# STM32WL3Rx register map
File version: 1.0
Registers are 32-bit, read-write, reset 0x0 unless marked. A register's access mark holds for its fields unless they carry their own. Offsets are from the block's base; [hi:lo] are bit positions; {n}, {i} and the like mark numbered series.

## FLASH — FLASH (FLASH)
Base 0x40001000
0x00 COMMAND — (@ 0x00000000) Command register
  [7:0] COMMAND
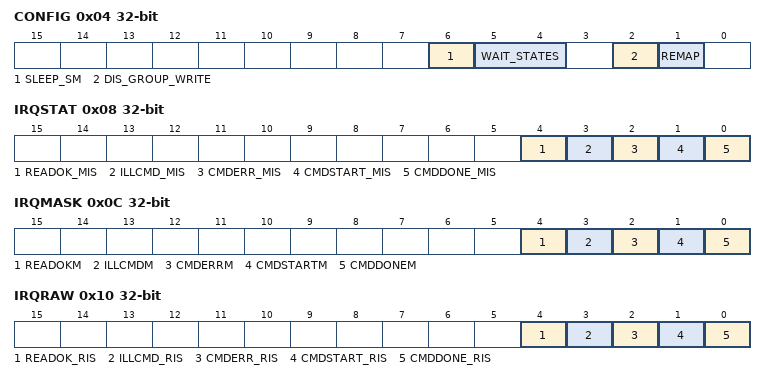
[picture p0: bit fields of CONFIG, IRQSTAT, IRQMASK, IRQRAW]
0x04 CONFIG — (@ 0x00000004) Configuration register
  [6] SLEEP_SM, [5:4] WAIT_STATES, [2] DIS_GROUP_WRITE, [1] REMAP
0x08 IRQSTAT — (@ 0x00000008) Interrupt status register
  [4] READOK_MIS, [3] ILLCMD_MIS, [2] CMDERR_MIS, [1] CMDSTART_MIS, [0] CMDDONE_MIS
0x0C IRQMASK — (@ 0x0000000C) Interrupt mask register
  [4] READOKM, [3] ILLCMDM, [2] CMDERRM, [1] CMDSTARTM, [0] CMDDONEM
0x10 IRQRAW — (@ 0x00000010) Intertupt raw status register
  [4] READOK_RIS, [3] ILLCMD_RIS, [2] CMDERR_RIS, [1] CMDSTART_RIS, [0] CMDDONE_RIS
0x14 SIZE — (@ 0x00000014) SIZE register
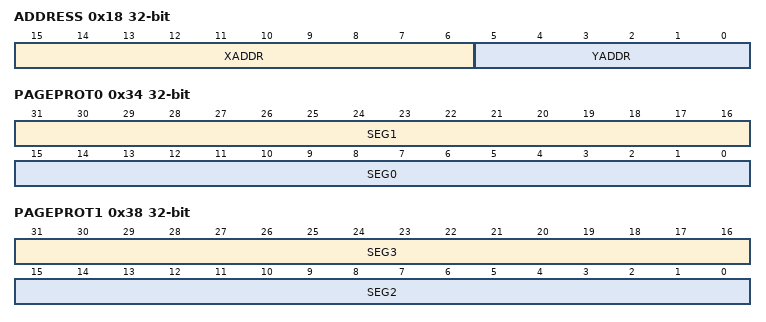
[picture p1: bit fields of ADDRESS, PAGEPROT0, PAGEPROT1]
0x18 ADDRESS — (@ 0x00000018) Address register
  [15:6] XADDR, [5:0] YADDR
0x24 LFSRVAL — (@ 0x00000024) LFSRVAL register
0x34 PAGEPROT0 — (@ 0x00000034) Main Flash page protection register 0
  [31:16] SEG1, [15:0] SEG0
0x38 PAGEPROT1 — (@ 0x00000038) Main Flash page protection register 1
  [31:16] SEG3, [15:0] SEG2
{0x40+4i} DATA{i} (i=0..3) — (@ {0x40+4i}) Data register {i}

## TIM2 — Advanced-timers (TIM)
Base 0x40002000
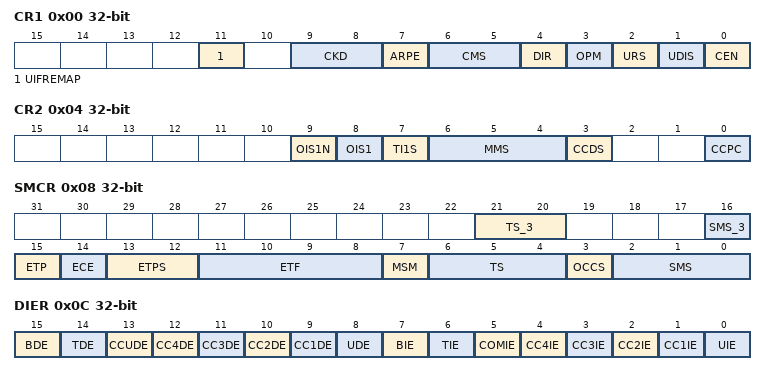
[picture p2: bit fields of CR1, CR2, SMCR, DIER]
0x00 CR1 — (@ 0x00000000) Control register 1
  [11] UIFREMAP
  [9:8] CKD
    0=DIV1 (tDTS=tCK_INT); 1=DIV2 (tDTS=2*tCK_INT); 2=DIV4 (tDTS=4*tCK_INT)
  [7] ARPE
  [6:5] CMS
  [4] DIR
    0=UP (Timer counter counts up); 1=DOWN (Timer counter counts down)
  [3] OPM
    1=SINGLE (Counter stops counting at the next update event); 0=REPETITIVE (Counter is not stopped at update event)
  [2] URS
    0=REGULAR (Counter overflow/underflow, Setting the UG bit or Update generation through the slave mode controller generates an update request); 1=COUNTER (Only counter overflow/underflow generates an update request)
  [1] UDIS
  [0] CEN
0x04 CR2 — (@ 0x00000004) Control register 2
  [9] OIS1N
  [8] OIS1
  [7] TI1S
  [6:4] MMS
    0=RESET (UG bit from the TIMx_EGR register is used as trigger output); 1=ENABLE (Counter Enable signal (CNT_EN) is used as trigger output); 2=UPDATE (Update event is used as trigger output); 3=CC1IF (CC1 capture or a compare match is used as trigger output); {v}=OC{v-3}REF (OC{v-3}REF signal is used as trigger output) (v=4..7)
  [3] CCDS
    0=CC (CCx DMA request sent when CCx event occurs); 1=UPDATE (CCx DMA requests sent when update event occurs)
  [0] CCPC
0x08 SMCR — (@ 0x00000008) Slave mode control register
  [21:20] TS_3
  [16] SMS_3
  [15] ETP
  [14] ECE
  [13:12] ETPS
  [11:8] ETF
  [7] MSM
  [6:4] TS
  [3] OCCS
    0=OCREF_CLR (OCREF_CLR_INT is connected to the OCREF_CLR input); 1=ETR (OCREF_CLR_INT is connected to ETRF)
  [2:0] SMS
0x0C DIER — (@ 0x0000000C) DMA/Interrupt enable register
  [15] BDE, [14] TDE, [13] CCUDE, [n+8] CC{n}DE (n=1..4), [8] UDE, [7] BIE, [6] TIE, [5] COMIE, [n] CC{n}IE (n=1..4), [0] UIE
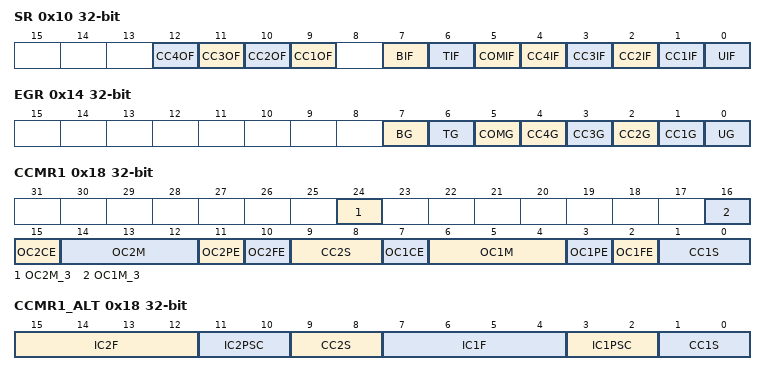
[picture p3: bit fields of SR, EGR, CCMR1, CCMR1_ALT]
0x10 SR — (@ 0x00000010) Status register
  [n+8] CC{n}OF (n=1..4), [7] BIF, [6] TIF, [5] COMIF, [n] CC{n}IF (n=1..4), [0] UIF
0x14 EGR — (@ 0x00000014) Event generation register
  [7] BG, [6] TG, [5] COMG, [n] CC{n}G (n=1..4), [0] UG
0x18 CCMR1 — (@ 0x00000018) Input capture and output compare mode register 1
  [24] OC2M_3, [16] OC1M_3, [15] OC2CE, [14:12] OC2M, [11] OC2PE, [10] OC2FE, [9:8] CC2S, [7] OC1CE, [6:4] OC1M, [3] OC1PE, [2] OC1FE, [1:0] CC1S
0x18 CCMR1_ALT (alternate view of CCMR1) — (@ 0x00000018) Input capture and output compare mode register 1
  [15:12] IC2F, [11:10] IC2PSC, [9:8] CC2S, [7:4] IC1F, [3:2] IC1PSC, [1:0] CC1S
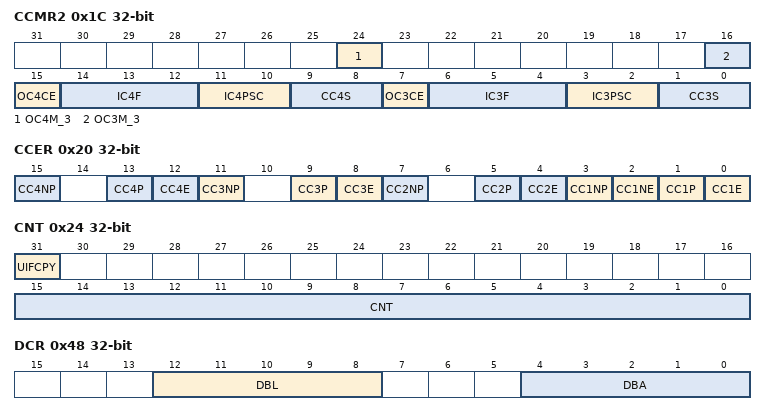
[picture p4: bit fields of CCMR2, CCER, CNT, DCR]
0x1C CCMR2 — (@ 0x0000001C) Input capture and output compare mode register 2
  [24] OC4M_3, [16] OC3M_3, [15] OC4CE, [14:12] IC4F, [11:10] IC4PSC, [9:8] CC4S, [7] OC3CE, [6:4] IC3F, [3:2] IC3PSC, [1:0] CC3S
0x20 CCER — (@ 0x00000020) Capture/compare enable register
  [4n-1] CC{n}NP (n=1..4), [4n-3] CC{n}P (n=1..4), [4n-4] CC{n}E (n=1..4), [2] CC1NE
0x24 CNT — (@ 0x00000024) Counter
  [31] UIFCPY, [15:0] CNT
0x28 PSC — (@ 0x00000028) Prescaler
  [15:0] PSC
0x2C ARR — (@ 0x0000002C) Auto-reload register
  [15:0] ARR
0x30 RCR — (@ 0x00000030) Repetition counter register
  [7:0] REP
{0x30+4i} CCR{i} (i=1..4) — (@ {0x30+4i}) Capture/compare register {i}
  [15:0] CCR{i}
0x44 BDTR — (@ 0x00000044) Break and dead-time register
  [26] BKDSRM
0x48 DCR — (@ 0x00000048) DMA control register
  [12:8] DBL, [4:0] DBA
0x4C DMAR — (@ 0x0000004C) DMA address for full transfer
  [15:0] DMAB
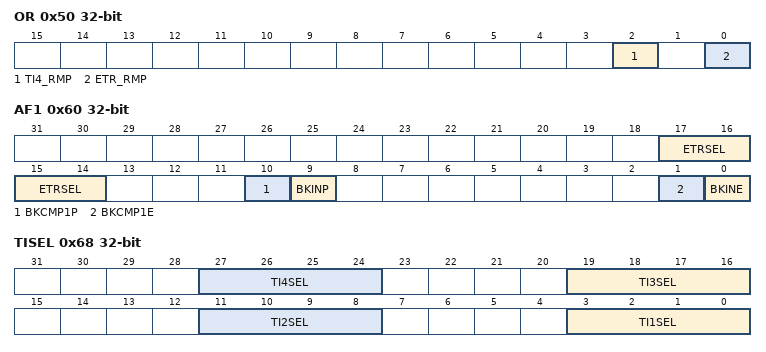
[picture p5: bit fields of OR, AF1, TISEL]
0x50 OR — (@ 0x00000050) Option register 1
  [2] TI4_RMP — TI4 RMP Input capture 4 remap
  [0] ETR_RMP — ETR_RMP External trigger remap
0x60 AF1 — (@ 0x00000060) TIM alternate function option register 1
  [17:14] ETRSEL, [10] BKCMP1P, [9] BKINP, [1] BKCMP1E, [0] BKINE
0x68 TISEL — (@ 0x00000068) Input selection register
  [8n-5:8n-8] TI{n}SEL (n=1..4)
